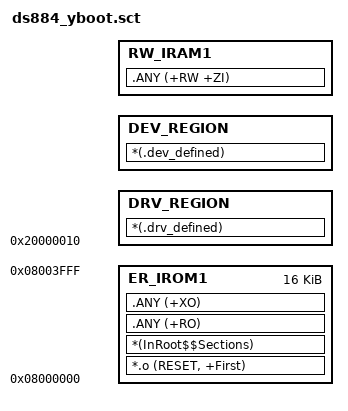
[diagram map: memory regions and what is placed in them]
; *************************************************************
; *** Scatter-Loading Description File generated by uVision ***
; *************************************************************

LR_IROM1 0x08000000 0x00004000  {    ; load region size_region
  ER_IROM1 0x08000000 0x00004000  {  ; load address = execution address
   *.o (RESET, +First)
   *(InRoot$$Sections)
   .ANY (+RO)
   .ANY (+XO)
  }
  DRV_REGION 0x20000010 {
    *(.drv_defined)
  }
  DEV_REGION +0 {
    *(.dev_defined)
  }
  RW_IRAM1 +0 {  ; RW data
   .ANY (+RW +ZI)
  }
}

